# ipro6s register map
Vendor: intelpro; Series: IPRO6S
CPU: ipro6s, little endian
Registers are 32-bit, read-write, reset 0x0 unless marked. A register's access mark holds for its fields unless they carry their own. Offsets are from the block's base; [hi:lo] are bit positions; {n}, {i} and the like mark numbered series; <NAME> marks a mode.

## BZ_PHY
Base 0x30003000
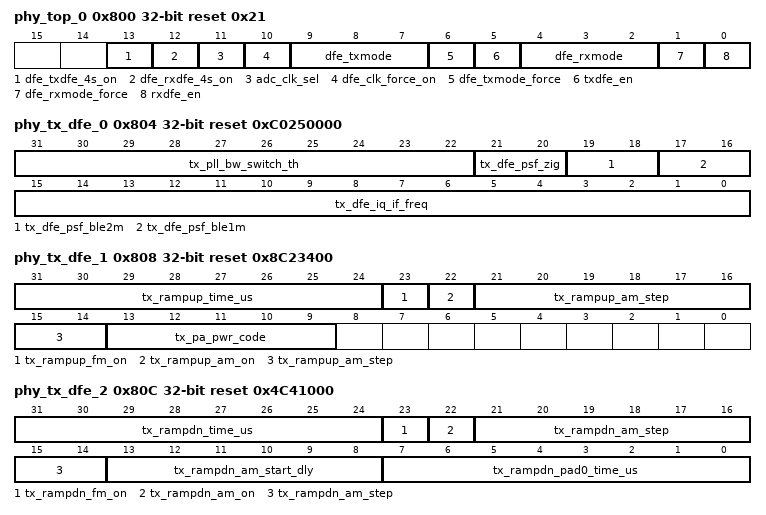
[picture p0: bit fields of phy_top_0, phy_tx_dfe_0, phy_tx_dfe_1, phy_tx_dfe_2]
0x800 phy_top_0 reset 0x21
  [13] dfe_txdfe_4s_on
  [12] dfe_rxdfe_4s_on
  [11] adc_clk_sel — 0:16m(602), 1:32m(702)
  [10] dfe_clk_force_on
  [9:7] dfe_txmode — 1:ble 2m 2:ble no coded 1m 3:ble coded 1m, 4:zigbee 2m, 6:bt
  [6] dfe_txmode_force
  [5] txdfe_en
  [4:2] dfe_rxmode — 1:ble 2m 2:ble no coded 1m 3:ble coded 1m, 4:zigbee 2m, 6:bt
  [1] dfe_rxmode_force
  [0] rxdfe_en
0x804 phy_tx_dfe_0 reset 0xC0250000
  [31:22] tx_pll_bw_switch_th, [21:20] tx_dfe_psf_zig, [19:18] tx_dfe_psf_ble2m, [17:16] tx_dfe_psf_ble1m, [15:0] tx_dfe_iq_if_freq
0x808 phy_tx_dfe_1 reset 0x8C23400
  [31:24] tx_rampup_time_us, [23] tx_rampup_fm_on, [22] tx_rampup_am_on, [21:14] tx_rampup_am_step, [13:9] tx_pa_pwr_code
0x80C phy_tx_dfe_2 reset 0x4C41000
  [31:24] tx_rampdn_time_us, [23] tx_rampdn_fm_on, [22] tx_rampdn_am_on, [21:14] tx_rampdn_am_step, [13:8] tx_rampdn_am_start_dly, [7:0] tx_rampdn_pad0_time_us
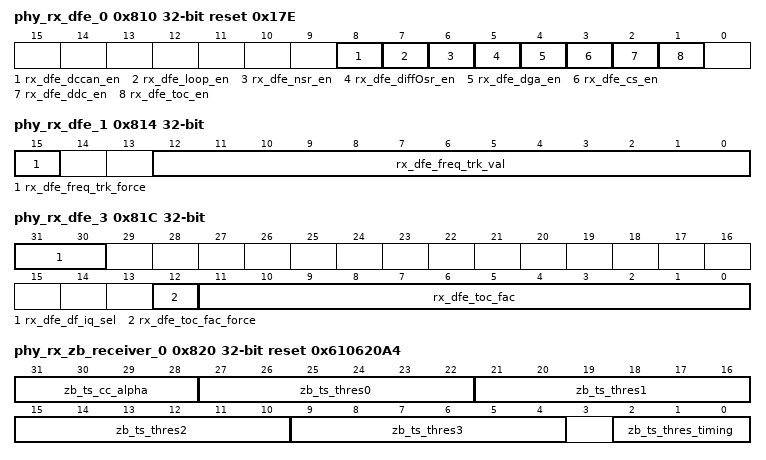
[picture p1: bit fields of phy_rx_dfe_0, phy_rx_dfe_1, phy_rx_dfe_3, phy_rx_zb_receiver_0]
0x810 phy_rx_dfe_0 reset 0x17E
  [8] rx_dfe_dccan_en
  [7] rx_dfe_loop_en — iqgen loop en
  [6] rx_dfe_nsr_en
  [5] rx_dfe_diffOsr_en
  [4] rx_dfe_dga_en
  [3] rx_dfe_cs_en
  [2] rx_dfe_ddc_en
  [1] rx_dfe_toc_en
0x814 phy_rx_dfe_1
  [15] rx_dfe_freq_trk_force, [12:0] rx_dfe_freq_trk_val
0x818 phy_rx_dfe_2 reset 0x800000
  [24:23] rx_dfe_dccan_alpha
0x81C phy_rx_dfe_3
  [31:30] rx_dfe_df_iq_sel, [12] rx_dfe_toc_fac_force, [11:0] rx_dfe_toc_fac
0x820 phy_rx_zb_receiver_0 reset 0x610620A4
  [31:28] zb_ts_cc_alpha — cross corr alpha filter, 6/16
  [27:22] zb_ts_thres0 — timingsync start thres, bipt change
  [21:16] zb_ts_thres1 — timingsync peak thres 1, bipt change
  [15:10] zb_ts_thres2 — timingsync peak thres 2, bipt change
  [9:4] zb_ts_thres3 — timingsync peak thres 3, bipt change
  [2:0] zb_ts_thres_timing — timingsync peak timing difference thres
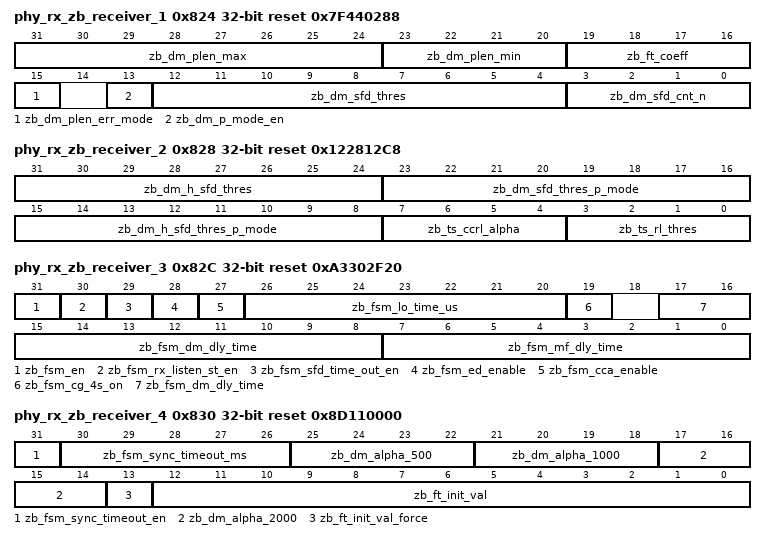
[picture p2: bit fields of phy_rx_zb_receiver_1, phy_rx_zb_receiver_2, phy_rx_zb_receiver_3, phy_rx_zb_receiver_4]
0x824 phy_rx_zb_receiver_1 reset 0x7F440288
  [31:24] zb_dm_plen_max — max phy length bytes, if phy length > max phy_len_error = 1
  [23:20] zb_dm_plen_min — min phy length bytes, if phy length < min phy_len_error = 1
  [19:16] zb_ft_coeff — frequency tracking coeff, 4/16
  [15] zb_dm_plen_err_mode
  [13] zb_dm_p_mode_en
  [12:4] zb_dm_sfd_thres — sfd sync thres, 40/4
  [3:0] zb_dm_sfd_cnt_n — sfd time out cnt
0x828 phy_rx_zb_receiver_2 reset 0x122812C8
  [31:24] zb_dm_h_sfd_thres
  [23:16] zb_dm_sfd_thres_p_mode
  [15:8] zb_dm_h_sfd_thres_p_mode
  [7:4] zb_ts_ccrl_alpha — cross corr ref lvl alpha filter, 12/1024
  [3:0] zb_ts_rl_thres — cross corr ref lvl thres coeff, 8
0x82C phy_rx_zb_receiver_3 reset 0xA3302F20
  [31] zb_fsm_en
  [30] zb_fsm_rx_listen_st_en
  [29] zb_fsm_sfd_time_out_en
  [28] zb_fsm_ed_enable
  [27] zb_fsm_cca_enable
  [26:20] zb_fsm_lo_time_us
  [19] zb_fsm_cg_4s_on
  [17:8] zb_fsm_dm_dly_time — sample timing ctrl in fsm
  [7:0] zb_fsm_mf_dly_time — sample timing ctrl in fsm
0x830 phy_rx_zb_receiver_4 reset 0x8D110000
  [31] zb_fsm_sync_timeout_en, [30:26] zb_fsm_sync_timeout_ms, [25:22] zb_dm_alpha_500, [21:18] zb_dm_alpha_1000, [17:14] zb_dm_alpha_2000, [13] zb_ft_init_val_force, [12:0] zb_ft_init_val
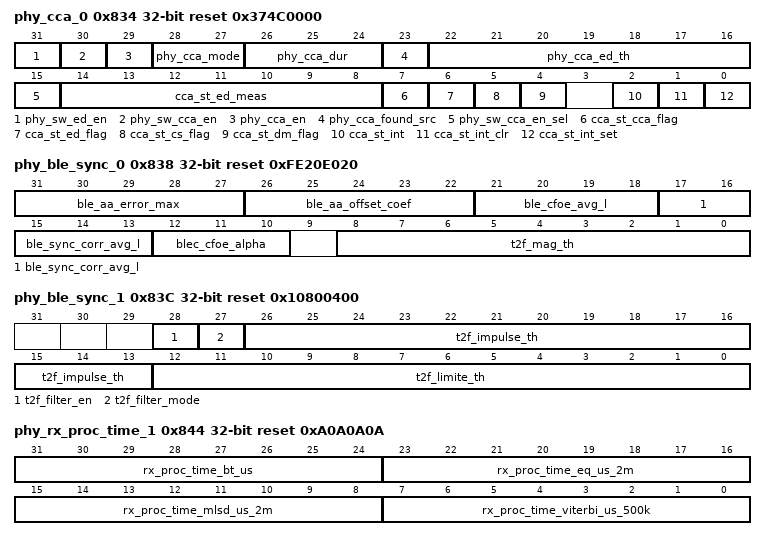
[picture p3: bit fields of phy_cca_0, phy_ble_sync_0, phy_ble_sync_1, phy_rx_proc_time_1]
0x834 phy_cca_0 reset 0x374C0000 (reset mask 0xFFFF8003)
  [31] phy_sw_ed_en
  [30] phy_sw_cca_en
  [29] phy_cca_en
  [28:27] phy_cca_mode
  [26:24] phy_cca_dur — 0: 16 us, 1 symbol 1: 32 us, 2 symbols 2: 48 us, 3 symbols 3: 64 us, 4 symbols 4: 80 us, 5 symbols 5: 96 us, 6 symbols 6:112 us, 7 symbols 7:128 us, 8 symbols
  [23] phy_cca_found_src
  [22:16] phy_cca_ed_th
  [15] phy_sw_cca_en_sel
  [14:8] cca_st_ed_meas ro
  [7] cca_st_cca_flag ro
  [6] cca_st_ed_flag ro
  [5] cca_st_cs_flag ro
  [4] cca_st_dm_flag ro
  [2] cca_st_int ro
  [1] cca_st_int_clr
  [0] cca_st_int_set
0x838 phy_ble_sync_0 reset 0xFE20E020
  [31:27] ble_aa_error_max
  [26:22] ble_aa_offset_coef — cfo est adj coeff, 24/32
  [21:18] ble_cfoe_avg_l — cfo est maw len
  [17:13] ble_sync_corr_avg_l — aa corr maw len
  [12:10] blec_cfoe_alpha
  [8:0] t2f_mag_th — t2f input vld mag thres, 32/256
0x83C phy_ble_sync_1 reset 0x10800400
  [28] t2f_filter_en
  [27] t2f_filter_mode
  [26:13] t2f_impulse_th — phase diff impulse det thres, 1024/8192
  [12:0] t2f_limite_th — phase diff limit, 1024/8192
0x840 phy_reserved_0 reset 0xFFFF
0x844 phy_rx_proc_time_1 reset 0xA0A0A0A
  [31:24] rx_proc_time_bt_us, [23:16] rx_proc_time_eq_us_2m, [15:8] rx_proc_time_mlsd_us_2m, [7:0] rx_proc_time_viterbi_us_500k
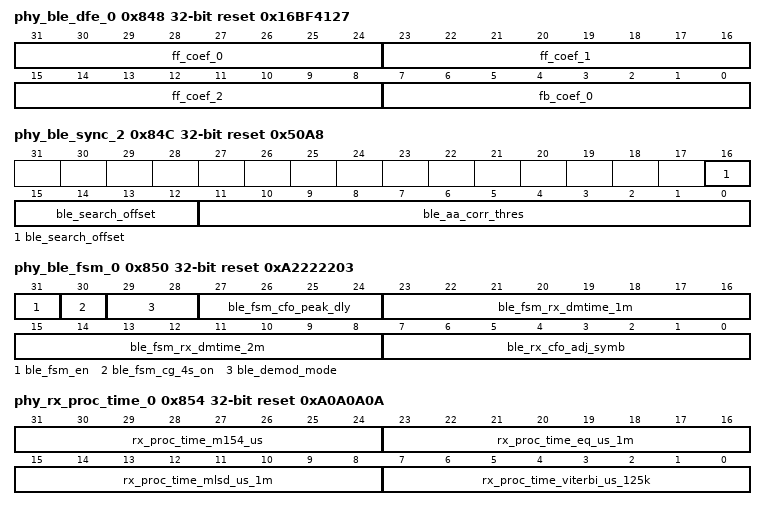
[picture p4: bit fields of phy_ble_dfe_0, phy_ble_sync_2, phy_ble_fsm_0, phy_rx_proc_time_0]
0x848 phy_ble_dfe_0 reset 0x16BF4127
  [31:24] ff_coef_0 — dfe equ
  [23:16] ff_coef_1 — dfe equ
  [15:8] ff_coef_2 — dfe equ
  [7:0] fb_coef_0 — dfe equ
0x84C phy_ble_sync_2 reset 0x50A8
  [16:12] ble_search_offset — ble search buffer update timing ctrl
  [11:0] ble_aa_corr_thres — aa corr sync thres
0x850 phy_ble_fsm_0 reset 0xA2222203
  [31] ble_fsm_en
  [30] ble_fsm_cg_4s_on
  [29:28] ble_demod_mode
  [27:24] ble_fsm_cfo_peak_dly — cfo peak feedback timing ctrl in fsm
  [23:16] ble_fsm_rx_dmtime_1m — sample timing ctrl in fsm
  [15:8] ble_fsm_rx_dmtime_2m — sample timing ctrl in fsm
  [7:0] ble_rx_cfo_adj_symb — cfo adj symbol number
0x854 phy_rx_proc_time_0 reset 0xA0A0A0A
  [31:24] rx_proc_time_m154_us, [23:16] rx_proc_time_eq_us_1m, [15:8] rx_proc_time_mlsd_us_1m, [7:0] rx_proc_time_viterbi_us_125k
0x858 phy_testbus_0 reset not defined
  [31:0] phy_testbus_read ro
0x85C phy_testbus_1 reset 0xF
  [3:0] phy_testbus_sel
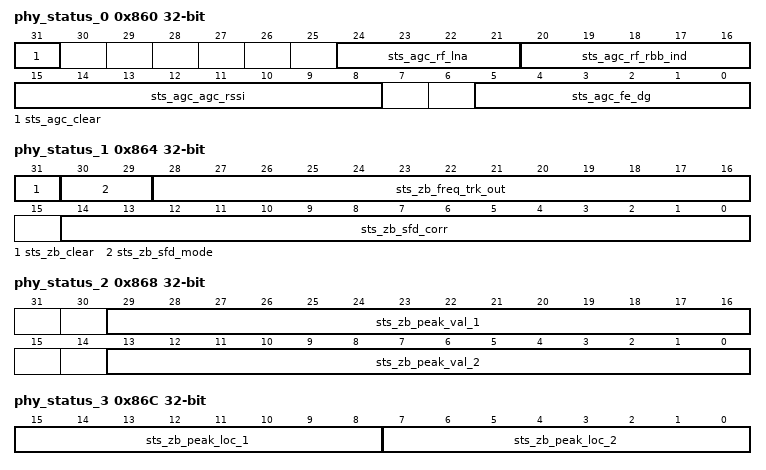
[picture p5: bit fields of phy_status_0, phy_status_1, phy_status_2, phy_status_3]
0x860 phy_status_0 (reset mask 0x80000000)
  [31] sts_agc_clear, [24:21] sts_agc_rf_lna ro, [20:16] sts_agc_rf_rbb_ind ro, [15:8] sts_agc_agc_rssi ro, [5:0] sts_agc_fe_dg ro
0x864 phy_status_1 (reset mask 0x80000000)
  [31] sts_zb_clear, [30:29] sts_zb_sfd_mode ro, [28:16] sts_zb_freq_trk_out ro, [14:0] sts_zb_sfd_corr ro
0x868 phy_status_2 reset not defined
  [29:16] sts_zb_peak_val_1 ro, [13:0] sts_zb_peak_val_2 ro
0x86C phy_status_3 reset not defined
  [15:8] sts_zb_peak_loc_1 ro, [7:0] sts_zb_peak_loc_2 ro
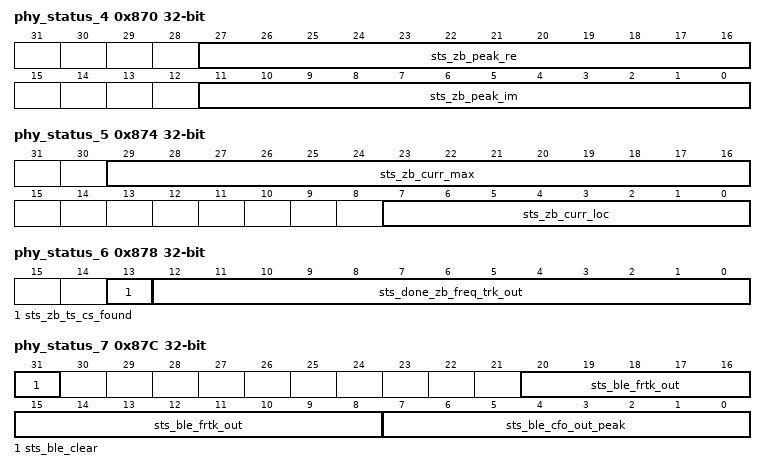
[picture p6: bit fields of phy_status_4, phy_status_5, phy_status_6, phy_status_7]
0x870 phy_status_4 reset not defined
  [27:16] sts_zb_peak_re ro, [11:0] sts_zb_peak_im ro
0x874 phy_status_5 reset not defined
  [29:16] sts_zb_curr_max ro, [7:0] sts_zb_curr_loc ro
0x878 phy_status_6 reset not defined
  [13] sts_zb_ts_cs_found ro, [12:0] sts_done_zb_freq_trk_out ro
0x87C phy_status_7 (reset mask 0x80000000)
  [31] sts_ble_clear, [20:8] sts_ble_frtk_out ro, [7:0] sts_ble_cfo_out_peak ro
0x880 phy_status_8 reset not defined
  [31:0] sts_ble_aa_confirm_bits ro
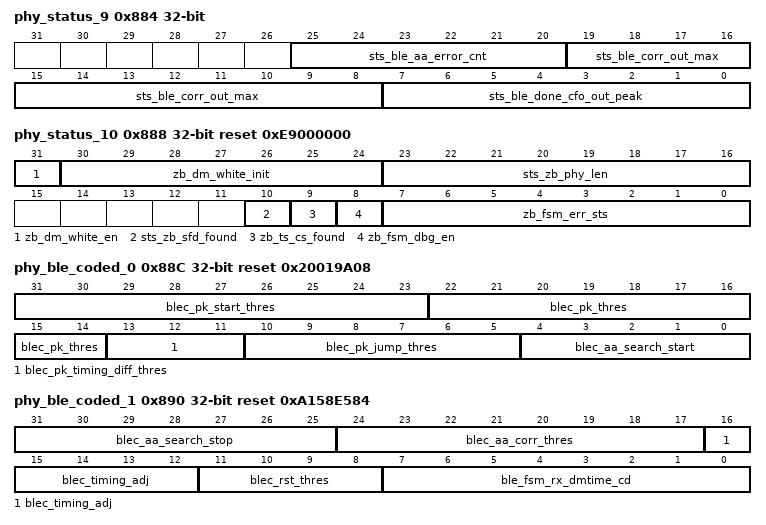
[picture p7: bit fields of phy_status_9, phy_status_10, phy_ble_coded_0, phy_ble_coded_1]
0x884 phy_status_9 reset not defined
  [25:20] sts_ble_aa_error_cnt ro, [19:8] sts_ble_corr_out_max ro, [7:0] sts_ble_done_cfo_out_peak ro
0x888 phy_status_10 reset 0xE9000000 (reset mask 0xFF000100)
  [31] zb_dm_white_en, [30:24] zb_dm_white_init, [23:16] sts_zb_phy_len ro, [10] sts_zb_sfd_found ro, [9] zb_ts_cs_found ro, [8] zb_fsm_dbg_en, [7:0] zb_fsm_err_sts ro
0x88C phy_ble_coded_0 reset 0x20019A08
  [31:23] blec_pk_start_thres, [22:14] blec_pk_thres, [13:11] blec_pk_timing_diff_thres, [10:5] blec_pk_jump_thres, [4:0] blec_aa_search_start
0x890 phy_ble_coded_1 reset 0xA158E584
  [31:25] blec_aa_search_stop
  [24:17] blec_aa_corr_thres
  [16:12] blec_timing_adj
  [11:8] blec_rst_thres
  [7:0] ble_fsm_rx_dmtime_cd — sample timing ctrl in fsm
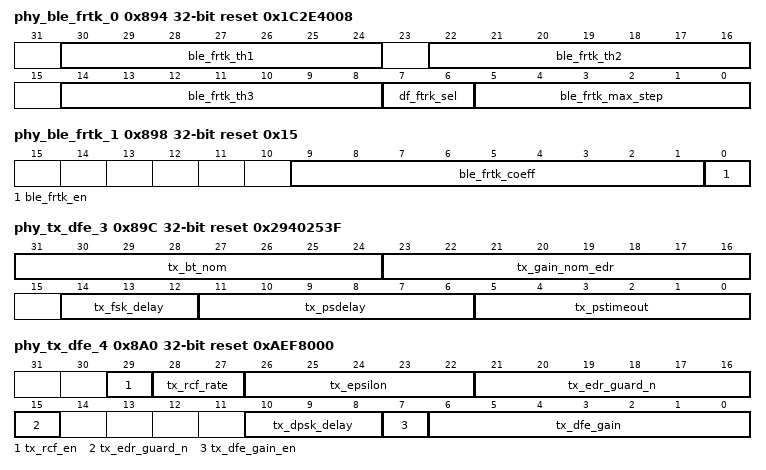
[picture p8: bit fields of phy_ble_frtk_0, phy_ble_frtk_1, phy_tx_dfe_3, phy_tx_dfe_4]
0x894 phy_ble_frtk_0 reset 0x1C2E4008
  [30:24] ble_frtk_th1, [22:16] ble_frtk_th2, [14:8] ble_frtk_th3, [7:6] df_ftrk_sel, [5:0] ble_frtk_max_step
0x898 phy_ble_frtk_1 reset 0x15
  [9:1] ble_frtk_coeff, [0] ble_frtk_en
0x89C phy_tx_dfe_3 reset 0x2940253F
  [31:24] tx_bt_nom, [23:16] tx_gain_nom_edr, [14:12] tx_fsk_delay, [11:6] tx_psdelay, [5:0] tx_pstimeout
0x8A0 phy_tx_dfe_4 reset 0xAEF8000
  [29] tx_rcf_en
  [28:27] tx_rcf_rate — 0:26M, 1:32M, 2:38.4M, 3:40M
  [26:22] tx_epsilon
  [21:15] tx_edr_guard_n
  [10:8] tx_dpsk_delay
  [7] tx_dfe_gain_en
  [6:0] tx_dfe_gain
0x8A4 phy_tx_dfe_5 reset 0x40000000
  [31:24] tx_gain_nom
0x8A8 phy_ble_coded_2
  [8:0] ci_time_out_th
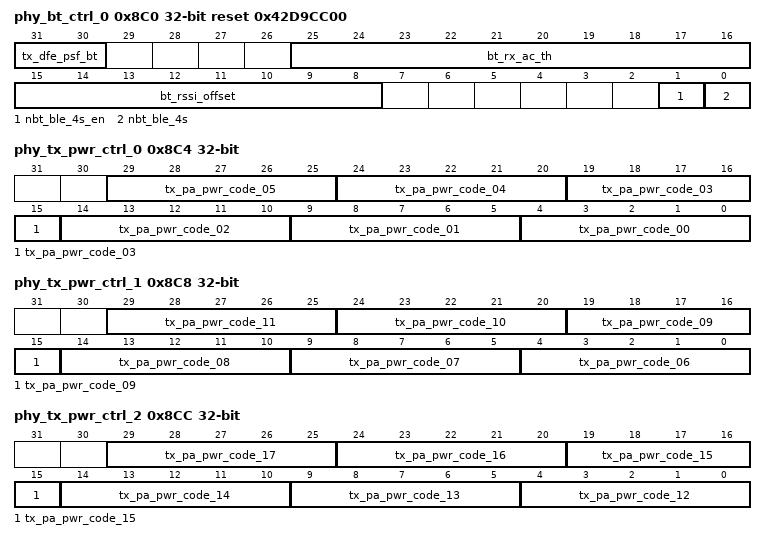
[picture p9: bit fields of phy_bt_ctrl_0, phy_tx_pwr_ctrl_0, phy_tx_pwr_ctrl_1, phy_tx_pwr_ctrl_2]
0x8C0 phy_bt_ctrl_0 reset 0x42D9CC00
  [31:30] tx_dfe_psf_bt
  [25:16] bt_rx_ac_th
  [15:8] bt_rssi_offset
  [1] nbt_ble_4s_en — 1:force nbt_ble
  [0] nbt_ble_4s — 0:BT, 1:BLE
0x8C4 phy_tx_pwr_ctrl_0
  [5n+4:5n] tx_pa_pwr_code_{n:02} (n=0..5)
0x8C8 phy_tx_pwr_ctrl_1
  [5n-26:5n-30] tx_pa_pwr_code_{n:02} (n=6..11)
0x8CC phy_tx_pwr_ctrl_2
  [5n-56:5n-60] tx_pa_pwr_code_{n} (n=12..17)
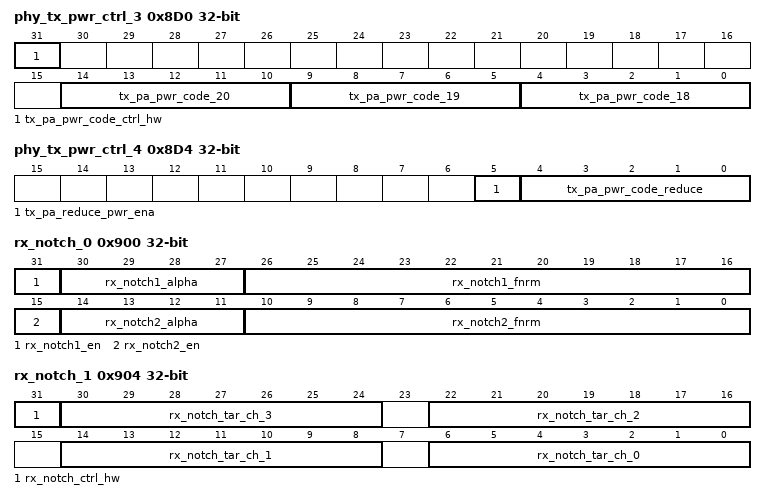
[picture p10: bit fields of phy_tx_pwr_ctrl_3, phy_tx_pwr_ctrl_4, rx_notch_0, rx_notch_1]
0x8D0 phy_tx_pwr_ctrl_3
  [31] tx_pa_pwr_code_ctrl_hw, [14:10] tx_pa_pwr_code_20, [9:5] tx_pa_pwr_code_19, [4:0] tx_pa_pwr_code_18
0x8D4 phy_tx_pwr_ctrl_4
  [5] tx_pa_reduce_pwr_ena, [4:0] tx_pa_pwr_code_reduce
0x900 rx_notch_0
  [31] rx_notch1_en, [30:27] rx_notch1_alpha, [26:16] rx_notch1_fnrm, [15] rx_notch2_en, [14:11] rx_notch2_alpha, [10:0] rx_notch2_fnrm
0x904 rx_notch_1
  [31] rx_notch_ctrl_hw, [8n+6:8n] rx_notch_tar_ch_{n} (n=0..3)
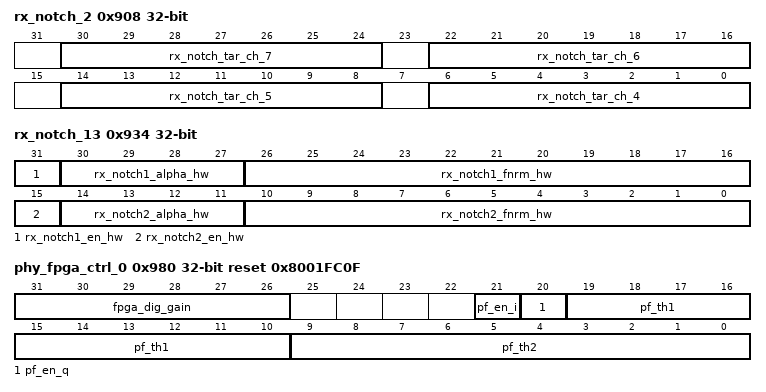
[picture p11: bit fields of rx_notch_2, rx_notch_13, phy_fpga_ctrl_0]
0x908 rx_notch_2
  [8n-26:8n-32] rx_notch_tar_ch_{n} (n=4..7)
0x90C rx_notch_3
  [6:0] rx_notch_tar_ch_8
0x910 rx_notch_4
  [31:0] rx_notch_para_0 — [31] rx_notch1_en [30:27] rx_notch1_alpha [26:16] rx_notch1_fnrm [15] rx_notch2_en [14:11] rx_notch2_alpha [10:0] rx_notch2_fnrm
{0x900+4i} rx_notch_{i} (i=5..12)
  [31:0] rx_notch_para_{i-4}
0x934 rx_notch_13 reset not defined
  [31] rx_notch1_en_hw ro, [30:27] rx_notch1_alpha_hw ro, [26:16] rx_notch1_fnrm_hw ro, [15] rx_notch2_en_hw ro, [14:11] rx_notch2_alpha_hw ro, [10:0] rx_notch2_fnrm_hw ro
0x980 phy_fpga_ctrl_0 reset 0x8001FC0F
  [31:26] fpga_dig_gain, [21] pf_en_i, [20] pf_en_q, [19:10] pf_th1, [9:0] pf_th2
